# haltium_application register map
Vendor: Nordic Semiconductor; Series: nRFHaltium; File version: 1
CPU: CM33 r0p4, little endian, MPU, FPU, 3 interrupt priority bits, 480 interrupts
Registers are 32-bit, read-write, reset 0x0 unless marked. A register's access mark holds for its fields unless they carry their own. Offsets are from the block's base; [hi:lo] are bit positions; lines under a group give offsets from that group; {n}, {i} and the like mark numbered series; 'fields as' and 'values as' point back to an identical list.

## ICACHEDATA_S — CACHEDATA 0
Base 0x12F00000
Same registers: DCACHEDATA_S 0x32F00000
{0x0+0x40*i} SET[{i}] (i=0..255) group — Unspecified
  {0x0+0x20*j} WAY[{j}] (j=0..1) group — Unspecified
    {0x0+8k} DU[{k}] (k=0..3) group — Unspecified
      {0x0+4l} DATA[{l}] (l=0..1) — Description collection: Cache data bits for DATA[q] in DU[p] (DataUnit) of SET[n], WAY[o].
        [31:0] Data ro

## ICACHEINFO_S — CACHEINFO 0
Base 0x12F10000
Same registers: DCACHEINFO_S 0x32F10000
{0x0+8i} SET[{i}] (i=0..255) group — Unspecified
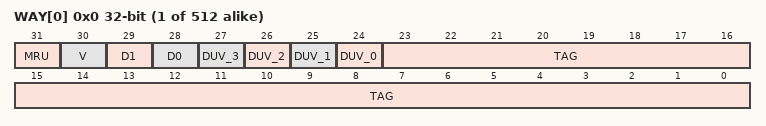
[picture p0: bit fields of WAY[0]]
  {0x0+4j} WAY[{j}] (j=0..1) — Description collection: Cache information for SET[n], WAY[o].
    [31] MRU ro — Most recently used way.
      0=Way0 was most recently used; 1=Way1 was most recently used
    [30] V ro — Line valid bit.
      0=Invalid cache line; 1=Valid cache line
    [29] D1 ro — Dirty data unit 1.
      0=Clean data unit; 1=Dirty data unit
    [28] D0 ro — Dirty data unit 0.
      0=Clean data unit; 1=Dirty data unit
    [n+24] DUV_{n} ro (n=0..3) — Data unit valid info.
      0=Invalid data unit; 1=Valid data unit
    [23:0] TAG ro — Cache tag.

## GLOBAL_STMDATA_NS — System Trace Macrocell data buffer 0
Base 0xA0000000
Same registers: GLOBAL_STMDATA_S 0xA0000000 (alternate view of GLOBAL_STMDATA_NS)
{0x0+0x2000000*i} DOMAIN[{i}] (i=0..15) group — Unspecified
  {0x0+j} NSDATA[{j}] (j=0..16777215) 8-bit — Description collection: NonSecure STM output data buffer for domain n. Writes to this region generates trace packets with id n+96.
  {0x1000000+j} SDATA[{j}] (j=0..16777215) 8-bit — Description collection: Secure STM output data buffer for domain n. Writes to this region generates trace packets with id n+32.
{0x0+0x1000000*i} BUFFER[{i}] (i=0..15) group (alternate view of DOMAIN[{i}]) — Raw buffer access to STM array. Use when DOMAIN array does not apply.
  {0x0+j} DATA[{j}] (j=0..16777215) 8-bit — Description collection: STM output data buffer n. Writes to this region generates trace packets.

## GLOBAL_TDDCONF_NS — TDDCONF 0
Base 0xBF001000
Same registers: GLOBAL_TDDCONF_S 0xBF001000 (alternate view of GLOBAL_TDDCONF_NS)
0x400 SYSPWRUPREQ — System power-up request
  [0] ACTIVE — Activate power-up request
    0=NotActive (Power-up request not active); 1=Active (Power-up request active)
0x404 DBGPWRUPREQ — Debug power-up request
  fields as SYSPWRUPREQ
0x408 TRACEPORTSPEED — Trace port trace clock speed
  [1:0] SPEED — Trace clock speed
    0=Speed25MHz; 1=Speed12500KHz (Speed 12.5MHz); 2=Speed6250KHz (Speed 6.25MHz); 3=Speed3125KHz (Speed 3.125MHz)
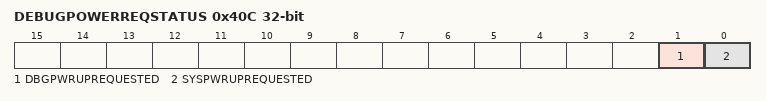
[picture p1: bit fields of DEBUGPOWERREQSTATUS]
0x40C DEBUGPOWERREQSTATUS ro — Combined effective system status of both SWJ-DP and TDDCONF registers originated power requests
  [1] DBGPWRUPREQUESTED — Debug domain powerup request status
    0=NoPowerReq (Power not requested); 1=Power requested
  [0] SYSPWRUPREQUESTED — System powerup request status
    0=NoPowerReq (Power not requested); 1=Power requested

## GLOBAL_TBM_NS — Trace buffer monitor 0
Base 0xBF003000
Same registers: GLOBAL_TBM_S 0xBF003000 (alternate view of GLOBAL_TBM_NS)
0x00 TASKS_START wo — Start counter
  [0] TASKS_START
    1=Trigger task
0x04 TASKS_STOP wo — Stop counter, clear counter value
  [0] TASKS_STOP
    1=Trigger task
0x08 TASKS_FLUSH wo — Stop counter, keep current counter value
  [0] TASKS_FLUSH
    1=Trigger task
0x100 EVENTS_HALFFULL — Counter value equals half-full
  [0] EVENTS_HALFFULL
    0=NotGenerated (Event not generated); 1=Generated (Event generated)
0x104 EVENTS_FULL — Counter value equals full
  [0] EVENTS_FULL
    values as EVENTS_HALFFULL.EVENTS_HALFFULL
0x108 EVENTS_FLUSH — Counter stopped due to flush
  [0] EVENTS_FLUSH
    values as EVENTS_HALFFULL.EVENTS_HALFFULL
0x200 SHORTS — Shortcuts between local events and tasks
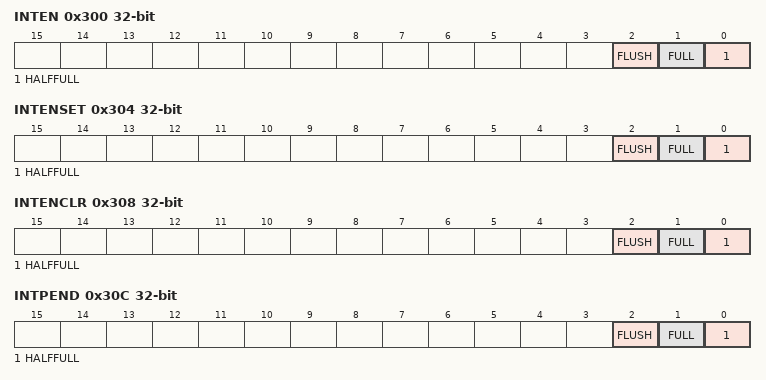
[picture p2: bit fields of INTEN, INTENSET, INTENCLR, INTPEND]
0x300 INTEN — Enable or disable interrupt
  [all] fields
    0=Disabled; 1=Enabled
  [2] FLUSH — Enable or disable interrupt for event FLUSH
  [1] FULL — Enable or disable interrupt for event FULL
  [0] HALFFULL — Enable or disable interrupt for event HALFFULL
0x304 INTENSET — Enable interrupt
  [all] fields
    on read: 0=Disabled (Read: Disabled); 1=Enabled (Read: Enabled) | on write: 1=Set (Enable)
  [2] FLUSH — Write '1' to enable interrupt for event FLUSH
  [1] FULL — Write '1' to enable interrupt for event FULL
  [0] HALFFULL — Write '1' to enable interrupt for event HALFFULL
0x308 INTENCLR — Disable interrupt
  [all] fields
    on read: 0=Disabled (Read: Disabled); 1=Enabled (Read: Enabled) | on write: 1=Clear (Disable)
  [2] FLUSH — Write '1' to disable interrupt for event FLUSH
  [1] FULL — Write '1' to disable interrupt for event FULL
  [0] HALFFULL — Write '1' to disable interrupt for event HALFFULL
0x30C INTPEND ro — Pending interrupts
  [all] fields
    on read: 0=NotPending (Read: Not pending); 1=Pending (Read: Pending)
  [2] FLUSH — Read pending status of interrupt for event FLUSH
  [1] FULL — Read pending status of interrupt for event FULL
  [0] HALFFULL — Read pending status of interrupt for event HALFFULL
0x400 BUFFERSIZE reset 0x1FF — System RAM trace buffer total size in bytes
  [11:0] BUFFERSIZE — Must only be configured in STOP mode. Must be multiple of 16 bytes to make half-buffer size always 64 bit word aligned. BUFFERSIZE LSB byte always fixed as 0xF to 16 bytes boundary. Minimum BUFFERSIZE value 0x00F i.e. 16 bytes, maximum value 0xFFF i.e. 4096 bytes.
    15=Min (16 bytes); 0xFFF=Max (4096 bytes)
0x404 COUNT ro — Counter current value
  [11:0] COUNT
